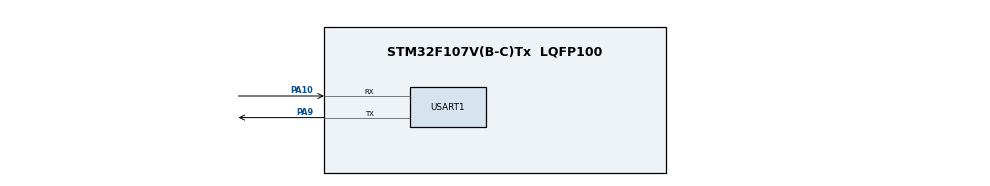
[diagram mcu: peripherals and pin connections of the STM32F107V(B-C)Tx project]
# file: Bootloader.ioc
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Mcu.Family=STM32F1
Mcu.Name=STM32F107V(B-C)Tx
Mcu.Package=LQFP100
NVIC.PriorityGroup=NVIC_PRIORITYGROUP_4
PA10.Mode=Asynchronous
PA10.Signal=USART1_RX
PA13.Mode=Serial_Wire
PA13.Signal=SYS_JTMS-SWDIO
PA14.Mode=Serial_Wire
PA14.Signal=SYS_JTCK-SWCLK
PA9.Mode=Asynchronous
PA9.Signal=USART1_TX
ProjectManager.HeapSize=0x200
ProjectManager.StackSize=0x400
ProjectManager.TargetToolchain=SW4STM32
RCC.USBFreq_Value=10666666.666666666
USART1.VirtualMode=VM_ASYNC
board=custom

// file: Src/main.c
/* USER CODE BEGIN Header */
/**
  ******************************************************************************
  * @file           : main.c
  * @brief          : Main program body
  ******************************************************************************
  * @attention
  *
  * <h2><center>&copy; Copyright (c) 2019 STMicroelectronics.
  * All rights reserved.</center></h2>
  *
  * This software component is licensed by ST under BSD 3-Clause license,
  * the "License"; You may not use this file except in compliance with the
  * License. You may obtain a copy of the License at:
  *                        opensource.org/licenses/BSD-3-Clause
  *
  ******************************************************************************
  */
/* USER CODE END Header */

#include "main.h"

/* USER CODE BEGIN Includes */
#include "menu.h"
#include "common.h"
/* USER CODE END Includes */

UART_HandleTypeDef huart1;

/* USER CODE BEGIN PV */
extern pFunction JumpToApplication;
extern uint32_t JumpAddress;
/* USER CODE END PV */

void SystemClock_Config(void);
static void MX_GPIO_Init(void);
static void MX_USART1_UART_Init(void);
/* USER CODE BEGIN PFP */
static void IAP_Init(void);
void SystemClock_Config(void);
/* USER CODE END PFP */

int main(void)
{
  /* USER CODE BEGIN 1 */
	uint8_t rx;
	uint8_t i,count=0;
  /* USER CODE END 1 */

  /* MCU Configuration--------------------------------------------------------*/

  /* Reset of all peripherals, Initializes the Flash interface and the Systick. */
  HAL_Init();

  /* Configure the system clock */
  SystemClock_Config();

  /* Initialize all configured peripherals */
  MX_GPIO_Init();
  MX_USART1_UART_Init();
  /* USER CODE BEGIN 2 */
  Serial_PutString("\r\nBootloader Up ...\r\n");

  RS485_RE(GPIO_PIN_RESET);HAL_Delay(2);
  for(i=0;i<50;i++)
  {
	  if ( HAL_UART_Receive(&huart1, &rx, 1, 2) == HAL_OK ){
		  if ( rx == '>' ){
			  count ++;
		  } else
			  break;
	  }
  }

  if ( count >= 3 ){
	/* Initialise Flash */
	FLASH_If_Init();
	/* Display main menu */
	Main_Menu ();
  }
  /* Keep the user application running */
  else
  {
    /* Test if user code is programmed starting from address "APPLICATION_ADDRESS" */
    if (((*(__IO uint32_t*)APPLICATION_ADDRESS) & 0x2FFE0000 ) == 0x20000000)
    {
      /* Jump to user application */
      JumpAddress = *(__IO uint32_t*) (APPLICATION_ADDRESS + 4);
      JumpToApplication = (pFunction) JumpAddress;
      /* Initialize user application's Stack Pointer */
      __set_MSP(*(__IO uint32_t*) APPLICATION_ADDRESS);
      JumpToApplication();
    } else {
      	/* Initialise Flash */
      	FLASH_If_Init();
        /* Display main menu */
        Main_Menu ();
    }
  }

  /* USER CODE END 2 */

  /* Infinite loop */
  while (1)
  {

  }
}

void SystemClock_Config(void)
{
  RCC_OscInitTypeDef RCC_OscInitStruct = {0};
  RCC_ClkInitTypeDef RCC_ClkInitStruct = {0};

  /** Initializes the CPU, AHB and APB busses clocks
  */
  RCC_OscInitStruct.OscillatorType = RCC_OSCILLATORTYPE_HSI;
  RCC_OscInitStruct.HSIState = RCC_HSI_ON;
  RCC_OscInitStruct.HSICalibrationValue = RCC_HSICALIBRATION_DEFAULT;
  RCC_OscInitStruct.PLL.PLLState = RCC_PLL_NONE;
  RCC_OscInitStruct.PLL2.PLL2State = RCC_PLL_NONE;
  if (HAL_RCC_OscConfig(&RCC_OscInitStruct) != HAL_OK)
  {
    Error_Handler();
  }
  /** Initializes the CPU, AHB and APB busses clocks
  */
  RCC_ClkInitStruct.ClockType = RCC_CLOCKTYPE_HCLK|RCC_CLOCKTYPE_SYSCLK
                              |RCC_CLOCKTYPE_PCLK1|RCC_CLOCKTYPE_PCLK2;
  RCC_ClkInitStruct.SYSCLKSource = RCC_SYSCLKSOURCE_HSI;
  RCC_ClkInitStruct.AHBCLKDivider = RCC_SYSCLK_DIV1;
  RCC_ClkInitStruct.APB1CLKDivider = RCC_HCLK_DIV1;
  RCC_ClkInitStruct.APB2CLKDivider = RCC_HCLK_DIV1;

  if (HAL_RCC_ClockConfig(&RCC_ClkInitStruct, FLASH_LATENCY_0) != HAL_OK)
  {
    Error_Handler();
  }
  /** Configure the Systick interrupt time
  */
  __HAL_RCC_PLLI2S_ENABLE();
}

static void MX_USART1_UART_Init(void)
{

  huart1.Instance = USART1;
  huart1.Init.BaudRate = 115200;
  huart1.Init.WordLength = UART_WORDLENGTH_8B;
  huart1.Init.StopBits = UART_STOPBITS_1;
  huart1.Init.Parity = UART_PARITY_NONE;
  huart1.Init.Mode = UART_MODE_TX_RX;
  huart1.Init.HwFlowCtl = UART_HWCONTROL_NONE;
  huart1.Init.OverSampling = UART_OVERSAMPLING_16;
  if (HAL_UART_Init(&huart1) != HAL_OK)
  {
    Error_Handler();
  }

}

static void MX_GPIO_Init(void)
{

  /* GPIO Ports Clock Enable */
  __HAL_RCC_GPIOA_CLK_ENABLE();

}

void Error_Handler(void)
{
}

/************************ (C) COPYRIGHT STMicroelectronics *****END OF FILE****/
